# CY8C5888LTI_LP097 register map
File version: 0.1
CY8C58LP
Registers are 8-bit, read-write, no defined reset value unless marked. A register's access mark holds for its fields unless they carry their own. Offsets are from the block's base; lines under a group give offsets from that group; [hi:lo] are bit positions; {n}, {i} and the like mark numbered series; 'fields as' and 'values as' point back to an identical list; <NAME> marks a mode.

## Memory map
0x00000000 PC — UART
0x00000000 ZYBO — UART

## PC — UART
Base 0x00000000
0x40006426 RX_PC_RX_ADDRESS1 — RX Address1 Register
0x40006436 RX_PC_RX_ADDRESS2 — RX Address2 Register
0x40006446 RX_PC_RX_DATA — RX Data Register
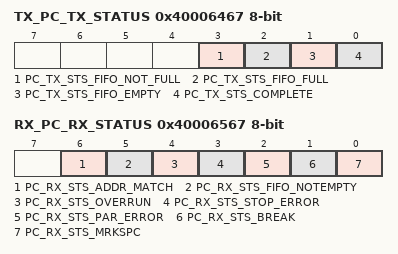
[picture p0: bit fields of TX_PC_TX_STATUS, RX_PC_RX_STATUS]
0x40006467 TX_PC_TX_STATUS — TX status register
  [3] PC_TX_STS_FIFO_NOT_FULL ro, [2] PC_TX_STS_FIFO_FULL ro, [1] PC_TX_STS_FIFO_EMPTY ro, [0] PC_TX_STS_COMPLETE ro
0x40006547 TX_PC_TX_DATA — TX Data Register
0x40006567 RX_PC_RX_STATUS — RX status register
  [6] PC_RX_STS_ADDR_MATCH ro, [5] PC_RX_STS_FIFO_NOTEMPTY ro, [4] PC_RX_STS_OVERRUN ro, [3] PC_RX_STS_STOP_ERROR ro, [2] PC_RX_STS_PAR_ERROR ro, [1] PC_RX_STS_BREAK ro, [0] PC_RX_STS_MRKSPC ro

## ZYBO — UART
Base 0x00000000
0x40006425 RX_ZYBO_RX_ADDRESS1 — RX Address1 Register
0x40006435 RX_ZYBO_RX_ADDRESS2 — RX Address2 Register
0x40006445 RX_ZYBO_RX_DATA — RX Data Register
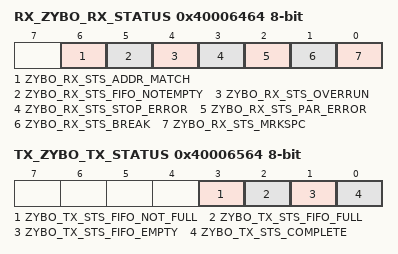
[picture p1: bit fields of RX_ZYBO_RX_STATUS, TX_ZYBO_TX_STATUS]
0x40006464 RX_ZYBO_RX_STATUS — RX status register
  [6] ZYBO_RX_STS_ADDR_MATCH ro, [5] ZYBO_RX_STS_FIFO_NOTEMPTY ro, [4] ZYBO_RX_STS_OVERRUN ro, [3] ZYBO_RX_STS_STOP_ERROR ro, [2] ZYBO_RX_STS_PAR_ERROR ro, [1] ZYBO_RX_STS_BREAK ro, [0] ZYBO_RX_STS_MRKSPC ro
0x40006544 TX_ZYBO_TX_DATA — TX Data Register
0x40006564 TX_ZYBO_TX_STATUS — TX status register
  [3] ZYBO_TX_STS_FIFO_NOT_FULL ro, [2] ZYBO_TX_STS_FIFO_FULL ro, [1] ZYBO_TX_STS_FIFO_EMPTY ro, [0] ZYBO_TX_STS_COMPLETE ro
